# MCXN236 register map
Vendor: nxp.com; File version: 1.0
CPU: CM33 r2p0, little endian, MPU, FPU, VTOR, 3 interrupt priority bits
Registers are 32-bit, read-write, reset 0x0 unless marked. A register's access mark holds for its fields unless they carry their own. Offsets are from the block's base; [hi:lo] are bit positions; {n}, {i} and the like mark numbered series.

## RTC_SUBSYSTEM0 — RTC_SUBSYSTEM
Base 0x4004C000; alternate view of RTC0
0x800 SUBSECOND_CTRL — Subsecond Control
  [0] SUB_SECOND_CNT_EN — Subsecond Counter Enable
    0=DISABLE; 1=ENABLE
0x804 SUBSECOND_CNT ro — Subsecond Counter
  [15:0] SUBSECOND_CNT — Current Subsecond Counter Value
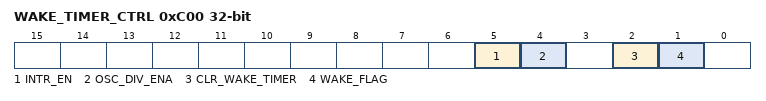
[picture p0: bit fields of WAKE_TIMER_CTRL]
0xC00 WAKE_TIMER_CTRL — Wake Timer Control
  [5] INTR_EN — Enable Interrupt
    0=DISABLE; 1=ENABLE
  [4] OSC_DIV_ENA — OSC Divide Enable
    0=DISABLE; 1=ENABLE
  [2] CLR_WAKE_TIMER wo — Clear Wake Timer
    0=DISABLE (No effect); 1=ENABLE (Clear the wake timer counter)
  [1] WAKE_FLAG write-1-clears — Wake Timer Status Flag
    0=DISABLE (Not timed out); 1=ENABLE (Timed out)
0xC0C WAKE_TIMER_CNT — Wake Timer Counter
  [31:0] WAKE_CNT — Wake Counter

## EIM0 — EIM
Base 0x4005B000
0x00 EIMCR — Error Injection Module Configuration Register
  [0] GEIEN — Global Error Injection Enable
    0=DISABLE (Disabled); 1=ENABLE (Enabled)
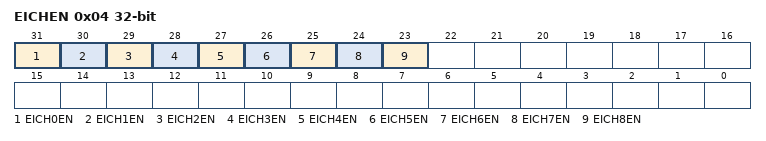
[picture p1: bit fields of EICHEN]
0x04 EICHEN — Error Injection Channel Enable register
  [31-n] EICH{n}EN (n=0..8) — Error Injection Channel {n} Enable
    0=DISABLE (Error injection is disabled on Error Injection Channel {n}); 1=ENABLE (Error injection is enabled on Error Injection Channel {n})
{0x100+0x40*i} EICHD{i}_WORD0 (i=0..6) — Error Injection Channel Descriptor {i}, Word0
  [31:25] CHKBIT_MASK — Checkbit Mask
{0x104+0x40*i} EICHD{i}_WORD1 (i=0..8) — Error Injection Channel Descriptor {i}, Word1
  [31:0] B0_3DATA_MASK — Data Mask Bytes 0-3
0x2C0 EICHD7_WORD0 — Error Injection Channel Descriptor 7, Word0
  [31] CHKBIT_MASK — Checkbit Mask
0x300 EICHD8_WORD0 — Error Injection Channel Descriptor 8, Word0
  [31:28] CHKBIT_MASK — Checkbit Mask

## ERM0 — ERM
Base 0x4005C000
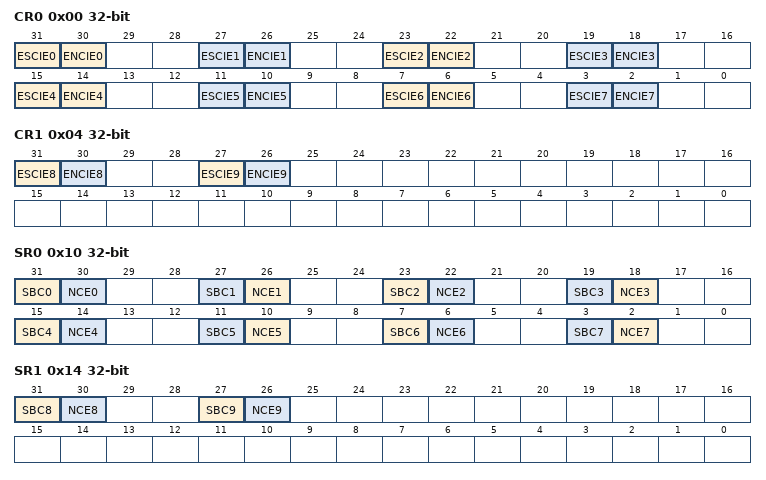
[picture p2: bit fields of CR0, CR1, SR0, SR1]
0x00 CR0 — ERM Configuration Register 0
  [31-4n] ESCIE{n} (n=0..7)
    0=DISABLE (Interrupt notification of Memory {n} single-bit correction events is disabled.); 1=ENABLE (Interrupt notification of Memory {n} single-bit correction events is enabled.)
  [30-4n] ENCIE{n} (n=0..7)
    0=DISABLE (Interrupt notification of Memory {n} non-correctable error events is disabled.); 1=ENABLE (Interrupt notification of Memory {n} non-correctable error events is enabled.)
0x04 CR1 — ERM Configuration Register 1
  [31] ESCIE8
    0=DISABLE (Interrupt notification of Memory 8 single-bit correction events is disabled.); 1=ENABLE (Interrupt notification of Memory 8 single-bit correction events is enabled.)
  [30] ENCIE8
    0=DISABLE (Interrupt notification of Memory 8 non-correctable error events is disabled.); 1=ENABLE (Interrupt notification of Memory 8 non-correctable error events is enabled.)
  [27] ESCIE9
    0=DISABLE (Interrupt notification of Memory 9 single-bit correction events is disabled.); 1=ENABLE (Interrupt notification of Memory 9 single-bit correction events is enabled.)
  [26] ENCIE9
    0=DISABLE (Interrupt notification of Memory 9 non-correctable error events is disabled.); 1=ENABLE (Interrupt notification of Memory 9 non-correctable error events is enabled.)
0x10 SR0 write-1-clears — ERM Status Register 0
  [31-4n] SBC{n} write-1-clears (n=0..4)
    0=NO_EVENT (No single-bit correction event on Memory {n} detected.); 1=EVENT (Single-bit correction event on Memory {n} detected.)
  [30-4n] NCE{n} write-1-clears (n=0..7)
    0=NO_ERROR (No non-correctable error event on Memory {n} detected.); 1=ERROR (Non-correctable error event on Memory {n} detected.)
  [11] SBC5 write-1-clears
    0=NO_EVENT (No single-bit correction event on Memory 5 detected.); 1=CORR_EVENT (Single-bit correction event on Memory 5 detected.)
  [7] SBC6 write-1-clears
    0=NO_EVENT (No single-bit correction event on Memory 6 detected.); 1=EVENT (Single-bit correction event on Memory 6 detected.)
  [3] SBC7 write-1-clears
    0=NO_EVENT (No single-bit correction event on Memory 7 detected.); 1=EVENT (Single-bit correction event on Memory 7 detected.)
0x14 SR1 write-1-clears — ERM Status Register 1
  [31] SBC8 write-1-clears
    0=NO_EVENT (No single-bit correction event on Memory 8 detected.); 1=EVENT (Single-bit correction event on Memory 8 detected.)
  [30] NCE8 write-1-clears
    0=NO_ERROR (No non-correctable error event on Memory 8 detected.); 1=ERROR (Non-correctable error event on Memory 8 detected.)
  [27] SBC9 write-1-clears
    0=NO_EVENT (No single-bit correction event on Memory 9 detected.); 1=EVENT (Single-bit correction event on Memory 9 detected.)
  [26] NCE9 write-1-clears
    0=NO_ERROR (No non-correctable error event on Memory 9 detected.); 1=ERROR (Non-correctable error event on Memory 9 detected.)
{0x100+0x10*i} EAR{i} ro (i=0..4) — ERM Memory {i} Error Address Register
  [31:0] EAR
{0x104+0x10*i} SYN{i} ro (i=0..4) — ERM Memory {i} Syndrome Register
  [31:24] SYNDROME
{0x108+0x10*i} CORR_ERR_CNT{i} (i=0..9) — ERM Memory {i} Correctable Error Count Register
  [7:0] COUNT — Memory n Correctable Error Count
0x184 SYN8 ro — ERM Memory 8 Syndrome Register
  [31:24] SYNDROME
